# Cortex-M4_RTSM register map
Vendor: ARM Ltd.
CPU: Cortex-M4_RTSM r0p0, little endian, MPU, FPU, VTOR, vendor SysTick, 8 interrupt priority bits
Registers are 32-bit, read-write, no defined reset value unless marked. A register's access mark holds for its fields unless they carry their own. Offsets are from the block's base; [hi:lo] are bit positions; {n}, {i} and the like mark numbered series.

## Control — System Control registers
Base ?
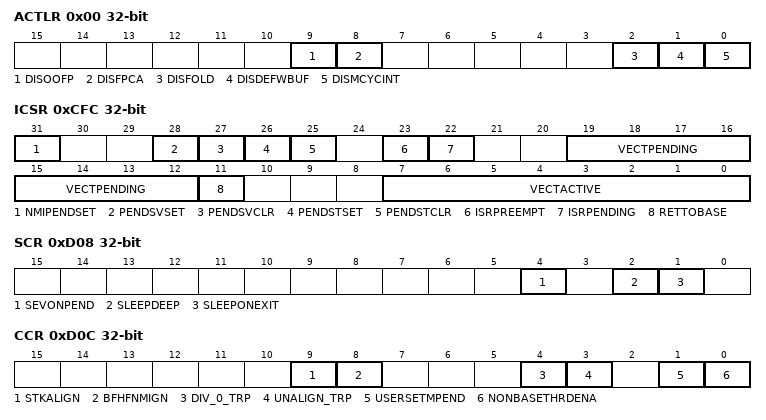
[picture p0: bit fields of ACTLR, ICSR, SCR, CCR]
0x00 ACTLR
  [9] DISOOFP — Disables floating point instructions completing out of order with respect to integer instructions
  [8] DISFPCA — Disable automatic update of CONTROL.FPCA
  [2] DISFOLD — Disables folding of IT instructions
  [1] DISDEFWBUF — Disables write buffer use during default memory map accesses
  [0] DISMCYCINT — Disables interruption of multi-cycle instructions
0xCFC ICSR
  [31] NMIPENDSET — Activates an NMI exception or reads back the current state
  [28] PENDSVSET — Sets a pending PendSV interrupt or reads back the current state
  [27] PENDSVCLR — Clears a pending PendSV interrupt
  [26] PENDSTSET — Sets a pending SysTick or reads back the current state
  [25] PENDSTCLR — Clears a pending SysTick, whether set here or by the timer hardware
  [23] ISRPREEMPT — Indicates whether a pending exception will be serviced on exit from debug halt state
  [22] ISRPENDING — Indicates if an external configurable, NVIC generated, interrupt is pending
  [19:12] VECTPENDING — The exception number for the highest priority pending exception. 0 indicates no pending exceptions
  [11] RETTOBASE — In Handler mode, indicates whether there is an active exception other than the exception indicated by the current value of the IPSR
  [7:0] VECTACTIVE — The exception number for the current executing exception
0xD00 VTOR
  [29] TBLBASE — Determines whether the vector table is in the code or SRAM memory region
  [30:7] TBLOFF — Bits [31:7] of the vector table address
0xD04 AIRCR
  [30:16] VECTKEY — Vector Key
  [30:16] VECTKEYSTAT
  [15] ENDIANNESS — Indicates the memory system data endianness
  [9:8] PRIGROUP — Priority grouping, indicates the binary point position.
  [2] SYSRESETREQ — System Reset Request
  [1] VECTCLRACTIVE — Clears all active state information for fixed and configurable exceptions
0xD08 SCR
  [4] SEVONPEND — Determines whether an interrupt transition from inactive state to pending state is a wakeup event
  [2] SLEEPDEEP — Hint indicating that waking from sleep might take longer
  [1] SLEEPONEXIT — whether, on an exit from an ISR that returns to the base level of execution priority, the processor enters a sleep state
0xD0C CCR
  [9] STKALIGN — Determines whether the exception entry sequence guarantees 8-byte stack frame alignment, adjusting the SP if necessary before saving state
  [8] BFHFNMIGN — Determines the effect of precise data access faults on handlers running at priority -1 or priority -2
  [4] DIV_0_TRP — Controls the trap on divide by 0
  [3] UNALIGN_TRP — Controls the trapping of unaligned word or halfword accesses
  [1] USERSETMPEND — Controls whether unprivileged software can access the STIR
  [0] NONBASETHRDENA — Controls whether the processor can enter Thread mode at an execution priority level other than base level
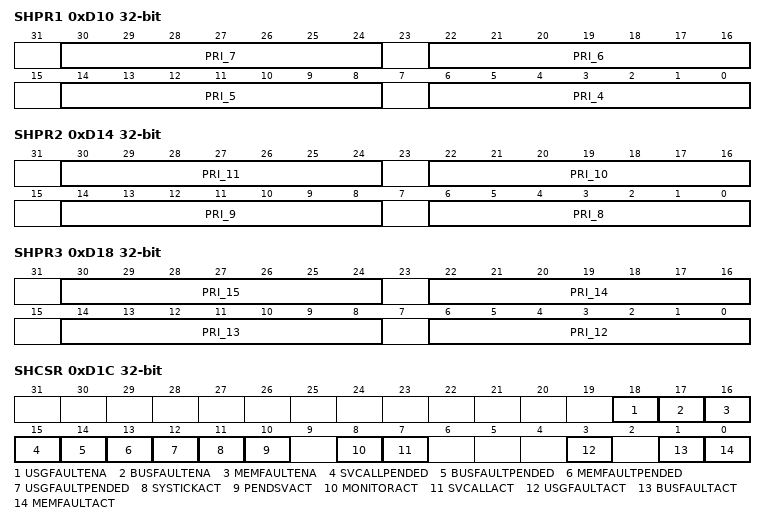
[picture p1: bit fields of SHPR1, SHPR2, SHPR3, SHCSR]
0xD10 SHPR1
  [30:24] PRI_7 — Priority of system handler 7
  [22:16] PRI_6 — Priority of system handler 6, UsageFault
  [14:8] PRI_5 — Priority of system handler 5, BusFault
  [6:0] PRI_4 — Priority of system handler 4, MemManage
0xD14 SHPR2
  [30:24] PRI_11 — Priority of system handler 11, SVCall
  [22:16] PRI_10 — Priority of system handler 10
  [14:8] PRI_9 — Priority of system handler 9
  [6:0] PRI_8 — Priority of system handler 8
0xD18 SHPR3
  [30:24] PRI_15 — Priority of system handler 15, SysTick
  [22:16] PRI_14 — Priority of system handler 14, PendSV
  [14:8] PRI_13 — Priority of system handler 13
  [6:0] PRI_12 — Priority of system handler 4, DebugMonitor
0xD1C SHCSR
  [18] USGFAULTENA — Enable UsageFault
  [17] BUSFAULTENA — Enable BusFault
  [16] MEMFAULTENA — Enable MemManage fault
  [15] SVCALLPENDED — SVCall pending
  [14] BUSFAULTPENDED — BusFault pending
  [13] MEMFAULTPENDED — MemManage pending
  [12] USGFAULTPENDED — UsageFault pending
  [11] SYSTICKACT — SysTick active
  [10] PENDSVACT — PendSV active
  [8] MONITORACT — Monitor active
  [7] SVCALLACT — SVCall active
  [3] USGFAULTACT — UsageFault active
  [1] BUSFAULTACT — BusFault active
  [0] MEMFAULTACT — MemManage active
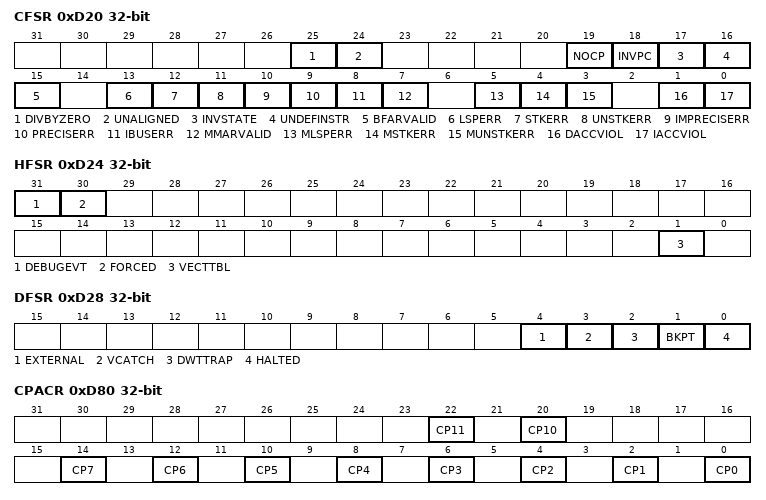
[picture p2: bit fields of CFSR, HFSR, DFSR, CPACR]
0xD20 CFSR
  [25] DIVBYZERO — Divide by zero error
  [24] UNALIGNED — Unaligned access error
  [19] NOCP — Coprocessor access error
  [18] INVPC — Integrity check error on EXC_RETURN
  [17] INVSTATE — Instruction executed with invalid EPSR.T or EPSR.IT field
  [16] UNDEFINSTR — Processor has attempted to execute an undefined instruction.
  [15] BFARVALID — BFAR has valid contents
  [13] LSPERR — Bus fault during FP lazy state preservation
  [12] STKERR — Derived bus fault on exception entry
  [11] UNSTKERR — Derived bus fault on exception return
  [10] IMPRECISERR — Imprecise data access error
  [9] PRECISERR — Precise data access error
  [8] IBUSERR — Bus fault on an instruction prefetch
  [7] MMARVALID — MMAR has valid contents
  [5] MLSPERR — MemManage fault during FP lazy state preservation
  [4] MSTKERR — Derived MemManage fault on exception entry
  [3] MUNSTKERR — Derived MemManage fault on exception return
  [1] DACCVIOL — Data access violation. The MMAR shows the data address that the load or store tried to access
  [0] IACCVIOL — MPU or Execute Never (XN) default memory map access violation on an instruction fetch
0xD24 HFSR
  [31] DEBUGEVT — Indicates a Debug event has occurred
  [30] FORCED — Indicates a fault with configurable priority has been escalated to a HardFault
  [1] VECTTBL — Indicates a fault has occurred because of a vector table read error on exception processing
0xD28 DFSR
  [4] EXTERNAL — Indicates a debug event generated because of the assertion of EDBGRQ
  [3] VCATCH — Indicates triggering of a Vector catch
  [2] DWTTRAP — Indicates a debug event generated by the DWT
  [1] BKPT — Indicates a debug event generated by BKPT instruction execution or a breakpoint match in FPB
  [0] HALTED — Indicates a debug event generated by C_HALT or C_STEP request or setting DEMCR.MON_STEP
0xD2C MMFAR
0xD30 BFAR
0xD34 AFSR
0xD80 CPACR
  [22] CP11 — Defines access permissions for the CP11 coprocessor.
  [20] CP10 — Defines access permissions for the CP10 coprocessor.
  [2n] CP{n} (n=0..7) — Defines access permissions for the CP{n} coprocessor.
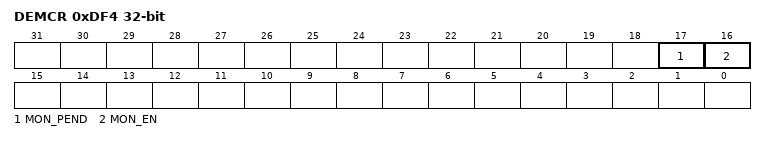
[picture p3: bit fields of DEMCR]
0xDF4 DEMCR ro
  [17] MON_PEND — Sets or clears the pending state of the DebugMonitor exception
  [16] MON_EN — Enable the DebugMonitor exception
0xEF8 STIR wo
  [7:0] INTID — Indicates the interrupt to be triggered. The value written is (ExceptionNumber - 16)
